# MIMXRT685S_cm33 register map
Vendor: nxp.com; File version: 1.0
CPU: CM33 r2p0, little endian, MPU, FPU, VTOR, 3 interrupt priority bits
Registers are 32-bit, read-write, reset 0x0 unless marked. A register's access mark holds for its fields unless they carry their own. Offsets are from the block's base; [hi:lo] are bit positions; {n}, {i} and the like mark numbered series; 'fields as' and 'values as' point back to an identical list.

## SCnSCB — System Control not in System Control Block
Base 0xE000E000
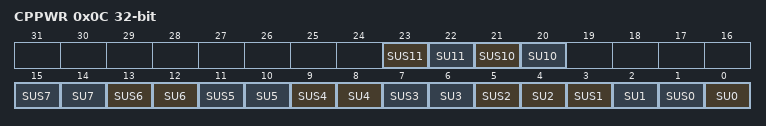
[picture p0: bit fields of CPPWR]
0x0C CPPWR reset not defined — Coprocessor Power Control Register
  [23] SUS11 — State UNKNOWN Secure only 11.
  [22] SU11 — State UNKNOWN 11.
  [21] SUS10 — State UNKNOWN Secure only 10.
    0=SECURE_AND_NON_SECURE (The SU10 field is accessible from both Security states.); 1=SECURE_ONLY (The SU10 field is only accessible from the Secure state.)
  [20] SU10 — State UNKNOWN 10.
    0=UNKNOWN_NOT_PERMITTED (The floating-point state is not permitted to become UNKNOWN.); 1=UNKNOWN_PERMITTED (The floating-point state is permitted to become UNKNOWN)
  [2n+1] SUS{n} (n=2..7) — State UNKNOWN Secure only {n}.
    0=SECURE_AND_NON_SECURE (The SU{n} field is accessible from both Security states.); 1=SECURE_ONLY (The SU{n} field is only accessible from the Secure state.)
  [2n] SU{n} (n=0..7) — State UNKNOWN {n}.
    0=UNKNOWN_NOT_PERMITTED (The coprocessor state is not permitted to become UNKNOWN.); 1=UNKNOWN_PERMITTED (The coprocessor state is permitted to become UNKNOWN.)
  [3] SUS1 — State UNKNOWN Secure only 1.
    0=SECURE_AND_NON_SECURE (The SU7 field is accessible from both Security states.); 1=SECURE_ONLY (The SU7 field is only accessible from the Secure state.)
  [1] SUS0 — State UNKNOWN Secure only 0.
    0=SECURE_AND_NON_SECURE (The SU0 field is accessible from both Security states.); 1=SECURE_ONLY (The SU0 field is only accessible from the Secure state.)

## NVIC — Nested Vectored Interrupt Controller
Base 0xE000E100
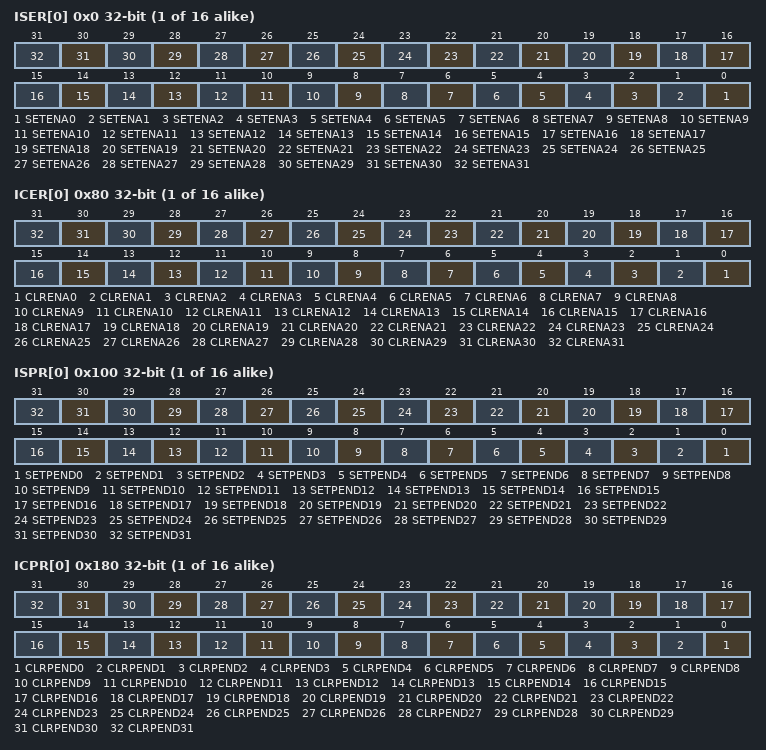
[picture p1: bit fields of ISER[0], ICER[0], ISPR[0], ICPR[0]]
{0x0+4i} ISER[{i}] (i=0..15) — Interrupt Set Enable Register
  [all] fields
    0=DISABLED (Write: No effect; Read: Interrupt 32n+m disabled); 1=ENABLED (Write: Enable interrupt 32n+m; Read: Interrupt 32n+m enabled)
  [n] SETENA{n} (n=0..31) — Interrupt set-enable bits.
{0x80+4i} ICER[{i}] (i=0..15) — Interrupt Clear Enable Register
  [all] fields
    values as the fields of ISER[0]
  [n] CLRENA{n} (n=0..31) — Interrupt clear-enable bits.
{0x100+4i} ISPR[{i}] (i=0..15) — Interrupt Set Pending Register
  [all] fields
    0=NOT_PENDING (Write: No effect; Read: Interrupt 32n+m is not pending); 1=PENDING (Write: Pend interrupt 32n+m; Read: Interrupt 32n+m pending)
  [n] SETPEND{n} (n=0..31) — Interrupt set-pending bits.
{0x180+4i} ICPR[{i}] (i=0..15) — Interrupt Clear Pending Register
  [all] fields
    0=NOT_PENDING (Write: No effect; Read: Interrupt 32n+m is not pending); 1=PENDING (Write: Clear pending state of interrupt 32n+m; Read: Interrupt 32n+m is pending)
  [n] CLRPEND{n} (n=0..31) — Interrupt clear-pending bits.
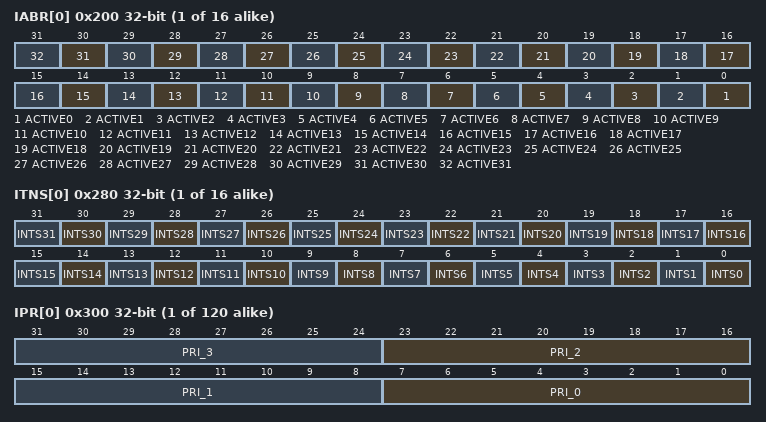
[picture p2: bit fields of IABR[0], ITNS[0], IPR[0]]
{0x200+4i} IABR[{i}] (i=0..15) reset not defined — Interrupt Active Bit Register
  [all] fields
    0=NOT_ACTIVE (The interrupt is not active.); 1=ACTIVE (The interrupt is active.)
  [n] ACTIVE{n} (n=0..31) — Active state bits.
{0x280+4i} ITNS[{i}] (i=0..15) reset not defined — Interrupt Target Non-secure Register
  [all] fields
    0=SECURE_STATE (The interrupt targets Secure state.); 1=NON_SECURE_STATE (The interrupt targets Non-secure state.)
  [n] INTS{n} (n=0..31) — Interrupt Targets Non-secure bits.
{0x300+4i} IPR[{i}] (i=0..119) reset not defined — Interrupt Priority Register
  [8n+7:8n] PRI_{n} (n=0..3)
0xE00 STIR wo — Software Trigger Interrupt Register
  [8:0] INTID — Interrupt ID of the interrupt to trigger, in the range 0-479.

## MPU — Memory Protection Unit
Base 0xE000ED90
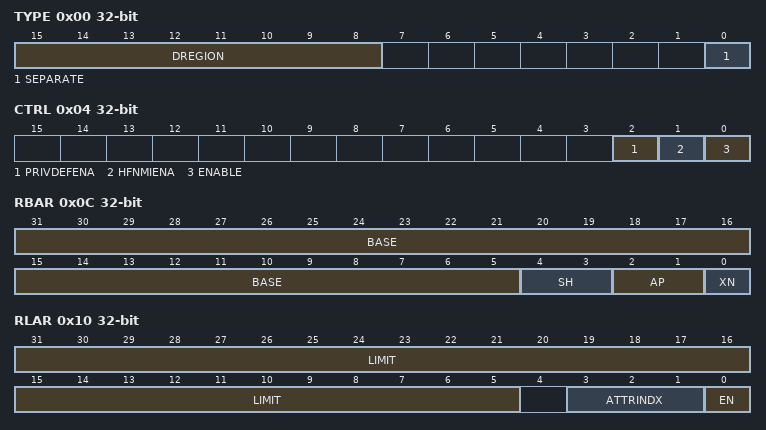
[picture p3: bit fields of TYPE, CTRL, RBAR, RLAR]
0x00 TYPE ro reset not defined — The MPU Type Register indicates how many regions the MPU support. Software can use it to determine if the processor implements an MPU.
  [15:8] DREGION — Number of regions supported by the MPU. If this field reads-as-zero the processor does not implement an MPU.
  [0] SEPARATE — Indicates support for separate instruction and data address maps. RAZ. Armv8-M only supports a unified MPU
0x04 CTRL — MPU Control Register.
  [2] PRIVDEFENA
    0=ENABLE (Disables the default memory map. Any instruction or data access that does not access a defined region faults.); 1=DISABLE (Enables the default memory map as a background region for privileged accesses.)
  [1] HFNMIENA — Enables the operation of MPU during HardFault and NMI handlers
    0=DISABLE (MPU is disabled during HardFault and NMI handlers.); 1=ENABLE (The MPU is enabled during HardFault and NMI handlers.)
  [0] ENABLE — Enables the MPU.
    0=MPU_DISABLE (The MPU is disabled.); 1=MPU_ENABLED (The MPU is enabled.)
0x08 RNR reset not defined — MPU Region Number Register.
  [7:0] REGION — Indicates the memory region accessed by MPU_RBAR and MPU_RASR.
0x0C RBAR reset not defined — MPU Region Base Address Register.
  [31:5] BASE — Contains bits[31:5] of the lower inclusive limit of the selected MPU memory region. This value is zero extended to provide the base address to be checked against.
  [4:3] SH — For Normal memory regions, the S bit indicates whether the region is shareable. For Strongly-ordered and Device memory, the S bit is ignored.
    0=NON_SHAREABLE (Non-shareable memory.); 1=UNPREDICTABLE; 2=OUTER_SHAREABLE; 3=INNER_SHAREABLE
  [2:1] AP — The AP[2:0] bits indicate the access and privilege properties of the region.
    0=PRIVILEGED_CODE (Read/write by privileged code only.); 1=PRIVILEGED_ANY (Read/write by any privilege level.); 2=PRIVILEGED_CODE_READ_ONLY (Read-only by privileged code only.); 3=PRIVILEGED_ANY_READ_ONLY (Read-only by any privilege level.)
  [0] XN — The XN bit is an Execute Never bit, that indicates whether the processor can execute instructions from the region.
    0=EXECUTE (Execution is only permitted if read permitted.); 1=EXECUTE_NEVER (Execution is not permitted.)
0x10 RLAR reset not defined — MPU Region Limit Address Register.
  [31:5] LIMIT — Limit address. Contains bits[31:5] of the upper inclusive limit of the selected MPU memory region. This value is postfixed with 0x1F to provide the limit address to be checked against.
  [3:1] ATTRINDX — Attribute index. Associates a set of attributes in the MPU_MAIR0 and MPU_MAIR1 fields.
  [0] EN — Enables this region.
    0=DISABLED (Region is disabled.); 1=ENABLED (Region is enabled.)
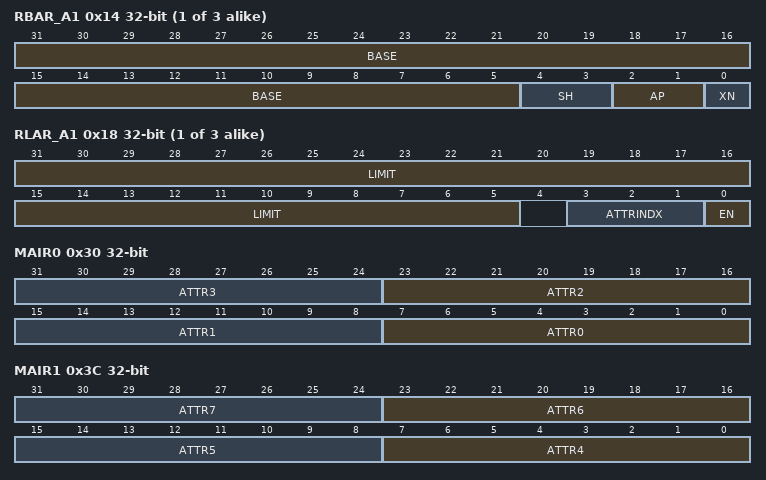
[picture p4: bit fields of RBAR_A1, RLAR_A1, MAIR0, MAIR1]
{0xC+8i} RBAR_A{i} reset not defined (i=1..3) — MPU Region Base Address Register.
  fields as RBAR
{0x10+8i} RLAR_A{i} reset not defined (i=1..3) — MPU Region Limit Address Register.
  fields as RLAR
0x30 MAIR0 reset not defined — MPU Memory Attribute Indirection Registers 0.
  [8n+7:8n] ATTR{n} (n=0..3) — Memory attribute encoding for MPU regions with an AttrIndex of {n}.
0x3C MAIR1 reset not defined — MPU Memory Attribute Indirection Registers 1.
  [8n-25:8n-32] ATTR{n} (n=4..7) — Memory attribute encoding for MPU regions with an AttrIndex of {n}.

## SAU — Security Attribution Unit
Base 0xE000EDD0
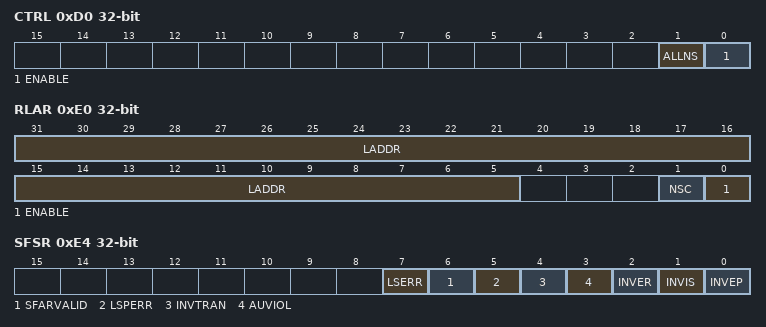
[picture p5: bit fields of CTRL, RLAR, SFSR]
0xD0 CTRL — Security Attribution Unit Control Register
  [1] ALLNS — All Non-secure.
    0=SECURED_MEMORY (Memory is marked as Secure and is not Non-secure callable.); 1=NON_SECURED_MEMORY (Memory is marked as Non-secure.)
  [0] ENABLE — Enable. Enables the SAU. This bit is RAZ/WI when the Security Extension is implemented without an SAU region.
    0=DISABLED (The SAU is disabled.); 1=ENABLED (The SAU is enabled.)
0xD4 TYPE — Security Attribution Unit Type Register
  [7:0] SREGION — SAU regions. The number of implemented SAU regions.
0xD8 RNR reset not defined — Security Attribution Unit Region Number Register
  [7:0] REGION — Region number.
0xDC RBAR reset not defined — Security Attribution Unit Region Base Address Register
  [31:5] BADDR — Base address. Holds bits[31:5] of the base address for the selected SAU region. Bits[4:0] of the base address are defined as 0x00.
0xE0 RLAR reset not defined — Security Attribution Unit Region Limit Address Register
  [31:5] LADDR — Limit address. Holds bits[31:5] of the limit address for the selected SAU region. Bits[4:0] of the limit address are defined as 0x1F.
  [1] NSC — Non-secure callable. Controls whether Non-secure state is permitted to execute an SG instruction from this region.
    0=NOT_NON_SECURE_CALLABLE (Region is not Non-secure callable.); 1=NON_SECURE_CALLABLE (Region is Non-secure callable.)
  [0] ENABLE — Enable. SAU region enable.
    0=ENABLED (SAU region is enabled.); 1=DISABLED (SAU region is disabled.)
0xE4 SFSR — Secure Fault Status Register
  [7] LSERR — Lazy state error flag.
    0=NO_ERROR (Error has not occurred); 1=ERROR (Error has occurred.)
  [6] SFARVALID — Secure fault address valid.
    0=NOT_VALID (SFAR content not valid.); 1=VALID (SFAR content valid.)
  [5] LSPERR — Lazy state preservation error flag.
    0=NO_ERROR (Error has not occurred.); 1=ERROR (Error has occurred.)
  [4] INVTRAN — Invalid transition flag.
    values as LSPERR
  [3] AUVIOL — Attribution unit violation flag.
    values as LSPERR
  [2] INVER — Invalid exception return flag.
    values as LSPERR
  [1] INVIS — Invalid integrity signature flag.
    values as LSPERR
  [0] INVEP — Invalid entry point.
    values as LSPERR
0xE8 SFAR reset not defined — Secure Fault Address Register
  [31:0] ADDRESS — When the SFARVALID bit of the SFSR is set to 1, this field holds the address of an access that caused an SAU violation.
